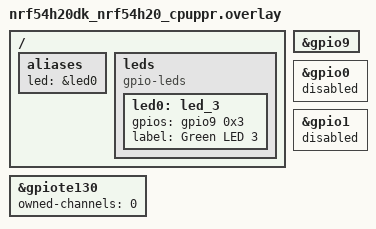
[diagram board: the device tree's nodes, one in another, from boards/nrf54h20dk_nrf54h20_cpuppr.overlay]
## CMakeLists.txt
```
#
# Copyright (c) 2024 Nordic Semiconductor
#
# SPDX-License-Identifier: LicenseRef-Nordic-5-Clause
#

cmake_minimum_required(VERSION 3.13.1)
find_package(Zephyr REQUIRED HINTS $ENV{ZEPHYR_BASE})
zephyr_include_directories(include)

project(i2c)

target_sources(app PRIVATE ./../common/main.c)
target_sources(app PRIVATE src/driver_test.c)

if(CONFIG_SOC_NRF54H20_CPUPPR)
  message(DEBUG "Power Mode handler for RISC V is included.")
  target_sources(app PRIVATE ${ZEPHYR_NRF_MODULE_DIR}/tests/benchmarks/multicore/common/power_off.c)
endif()
```

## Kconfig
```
#
# Copyright (c) 2025 Nordic Semiconductor ASA
#
# SPDX-License-Identifier: LicenseRef-Nordic-5-Clause
#

config APP_PROVIDE_PM_HOOKS
	bool "Application provides PM hooks"
	default y if SOC_NRF54H20_CPUPPR
	select HAS_PM
	select HAS_POWEROFF

source "Kconfig.zephyr"
```

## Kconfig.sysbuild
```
#
# Copyright (c) 2024 Nordic Semiconductor ASA
#
# SPDX-License-Identifier: LicenseRef-Nordic-5-Clause
#

source "share/sysbuild/Kconfig"

config REMOTE_BOARD
	string
	default "$(BOARD)/nrf54h20/cpurad" if SOC_NRF54H20
```

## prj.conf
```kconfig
# Drivers and peripherals
CONFIG_I2C=y
CONFIG_ASSERT=y

CONFIG_CONSOLE=n
CONFIG_UART_CONSOLE=n
CONFIG_SERIAL=n
CONFIG_BOOT_BANNER=n
CONFIG_NCS_BOOT_BANNER=n
CONFIG_LOG=n

CONFIG_GPIO=y
```

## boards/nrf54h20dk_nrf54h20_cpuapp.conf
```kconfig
CONFIG_SOC_NRF54H20_CPURAD_ENABLE=y

CONFIG_PM=y
CONFIG_PM_DEVICE=y
CONFIG_PM_DEVICE_RUNTIME=y
CONFIG_POWEROFF=y
```

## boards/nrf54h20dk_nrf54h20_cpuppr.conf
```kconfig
# Disable to limit code size
CONFIG_ASSERT=n
```

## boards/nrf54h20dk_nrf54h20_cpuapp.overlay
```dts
/ {
	aliases {
		led = &led0;
		/delete-property/ led1;
	};
};

/delete-node/ &led1;

&gpio6 {
	status = "disabled";
};

&exmif {
	status = "disabled";
};
```

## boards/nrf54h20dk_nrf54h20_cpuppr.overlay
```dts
/ {
	aliases {
		led = &led0;
	};

	leds {
		compatible = "gpio-leds";

		led0: led_3 {
			gpios = <&gpio9 0x3 0x0>;
			label = "Green LED 3";
		};
	};
};

&gpio9 {
	status = "okay";
};

&gpio0 {
	status = "disabled";
};

&gpio1 {
	status = "disabled";
};

&gpiote130 {
	status = "okay";
	owned-channels = <0>;
};
```

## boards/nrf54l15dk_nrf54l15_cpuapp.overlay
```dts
/* Can not use led_0 nor led_3 because pca63565
 * uses those GPIOs for other purposes.
 *
 * PPK takes cpuapp active/sleep state from P0.04
 * which is Button3 in the board definition.
 * Moreover, Buttons have (GPIO_PULL_UP | GPIO_ACTIVE_LOW).
 */

/ {
	aliases {
		led = &led_sw3;
		/delete-property/ sw3;
	};
};

/delete-node/ &button3;

/ {
	leds {
		led_sw3: led_sw3 {
			gpios = <&gpio0 4 GPIO_ACTIVE_HIGH>;
			label = "Change GPIO from Button3 to custom LED";
		};
	};
};
```

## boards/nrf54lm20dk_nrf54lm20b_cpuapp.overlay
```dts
/*
 * Copyright (c) 2026 Nordic Semiconductor ASA
 *
 * SPDX-License-Identifier: LicenseRef-Nordic-5-Clause
 */

/ {
	aliases {
		led = &led_custom0;
	};
};

/ {
	leds {
		led_custom0: led_custom0 {
			gpios = <&gpio3 0 GPIO_ACTIVE_HIGH>;
			label = "Custom LED due to collision with PCA63565";
		};
	};
};
```

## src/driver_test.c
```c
/*
 * Copyright (c) 2024 Nordic Semiconductor ASA
 *
 * SPDX-License-Identifier: LicenseRef-Nordic-5-Clause
 */

#include <zephyr/drivers/i2c.h>
#include <zephyr/kernel.h>

#define I2C_DEV_ADR (0x76)
#define REG_CHIP_ID_ADR (0xd0)
#define REG_CHIP_ID_VAL (0x61)

static const struct device *i2c = DEVICE_DT_GET(DT_ALIAS(sensor_bme688));

static bool suspend_req;

bool self_suspend_req(void)
{
	suspend_req = true;
	return true;
}

void thread_definition(void)
{
	int ret;
	uint8_t value;

	while (1) {
		if (suspend_req) {
			suspend_req = false;
			k_thread_suspend(k_current_get());
		}

		ret = i2c_reg_read_byte(i2c, I2C_DEV_ADR, REG_CHIP_ID_ADR, &value);
		__ASSERT(ret == 0, "i2c_reg_read_byte() returned %d", ret);

		/* Check if communication with bme688 was successful. */
		__ASSERT(value == REG_CHIP_ID_VAL,
			"Invalid CHIP_ID, got %u, expected %u\n", value, REG_CHIP_ID_VAL);
		value = 0;
	};
};
```
